# R7FA4L1BD register map
Vendor: Renesas Electronics Corporation; Series: RA4; File version: 0.90.02
CPU: CM33 r0p4, little endian, MPU, FPU, VTOR, 4 interrupt priority bits, 96 interrupts
Registers are 32-bit, read-write, reset 0x0 unless marked. A register's access mark holds for its fields unless they carry their own. Offsets are from the block's base; [hi:lo] are bit positions; {n}, {i} and the like mark numbered series.

## IIC0 — Inter,Integrated Circuit 0
Base 0x4009F000
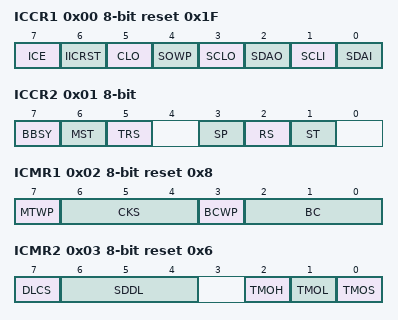
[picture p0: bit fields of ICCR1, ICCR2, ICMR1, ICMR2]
0x00 ICCR1 8-bit reset 0x1F — I2C Bus Control Register 1
  [7] ICE — I2C Bus Interface Enable
  [6] IICRST — I2C Bus Interface Internal Reset
  [5] CLO — Extra SCL Clock Cycle Output
  [4] SOWP wo — SCLO/SDAO Write Protect
  [3] SCLO — SCL Output Control/Monitor
  [2] SDAO — SDA Output Control/Monitor
  [1] SCLI ro — SCL Line Monitor
  [0] SDAI ro — SDA Line Monitor
0x01 ICCR2 8-bit — I2C Bus Control Register 2
  [7] BBSY ro — Bus Busy Detection Flag
  [6] MST — Master/Slave Mode
  [5] TRS — Transmit/Receive Mode
  [3] SP — Stop Condition Issuance Request
  [2] RS — Restart Condition Issuance Request
  [1] ST — Start Condition Issuance Request
0x02 ICMR1 8-bit reset 0x8 — I2C Bus Mode Register 1
  [7] MTWP — MST/TRS Write Protect
  [6:4] CKS — Internal Reference Clock Select
  [3] BCWP wo — BC Write Protect
  [2:0] BC — Bit Counter
0x03 ICMR2 8-bit reset 0x6 — I2C Bus Mode Register 2
  [7] DLCS — SDA Output Delay Clock Source Select
  [6:4] SDDL — SDA Output Delay Counter
  [2] TMOH — Timeout H Count Control
  [1] TMOL — Timeout L Count Control
  [0] TMOS — Timeout Detection Time Select
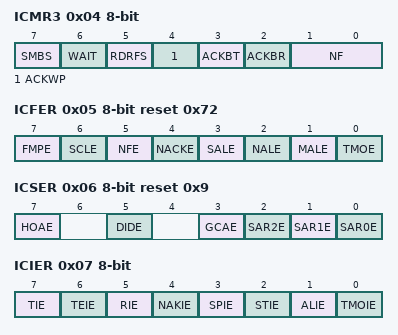
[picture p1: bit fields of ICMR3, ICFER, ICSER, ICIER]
0x04 ICMR3 8-bit — I2C Bus Mode Register 3
  [7] SMBS — SMBus/I2C Bus Select
  [6] WAIT — Low,hold is released by reading ICDRR.
  [5] RDRFS — RDRF Flag Set Timing Select
  [4] ACKWP — ACKBT Write Protect
  [3] ACKBT — Transmit Acknowledge
  [2] ACKBR ro — Receive Acknowledge
  [1:0] NF — Noise Filter Stage Select
0x05 ICFER 8-bit reset 0x72 — I2C Bus Function Enable Register
  [7] FMPE — Fast,Mode Plus Enable
  [6] SCLE — SCL Synchronous Circuit Enable
  [5] NFE — Digital Noise Filter Circuit Enable
  [4] NACKE — NACK Reception Transfer Suspension Enable
  [3] SALE — Slave Arbitration,Lost Detection Enable
  [2] NALE — NACK Transmission Arbitration,Lost Detection Enable
  [1] MALE — Master Arbitration,Lost Detection Enable
  [0] TMOE — Timeout Function Enable
0x06 ICSER 8-bit reset 0x9 — I2C Bus Status Enable Register
  [7] HOAE — Host Address Enable
  [5] DIDE — Device,ID Address Detection Enable
  [3] GCAE — General Call Address Enable
  [2] SAR2E — Slave Address Register 2 Enable
  [1] SAR1E — Slave Address Register 1 Enable
  [0] SAR0E — Slave Address Register 0 Enable
0x07 ICIER 8-bit — I2C Bus Interrupt Enable Register
  [7] TIE — Transmit Data Empty Interrupt Request Enable
  [6] TEIE — Transmit End Interrupt Request Enable
  [5] RIE — Receive Data Full Interrupt Request Enable
  [4] NAKIE — NACK Reception Interrupt Request Enable
  [3] SPIE — Stop Condition Detection Interrupt Request Enable
  [2] STIE — Start Condition Detection Interrupt Request Enable
  [1] ALIE — Arbitration,Lost Interrupt Request Enable
  [0] TMOIE — Timeout Interrupt Request Enable
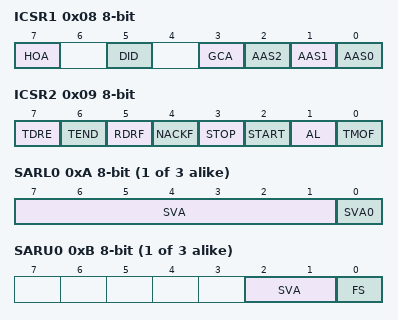
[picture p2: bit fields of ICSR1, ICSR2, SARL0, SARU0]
0x08 ICSR1 8-bit — I2C Bus Status Register 1
  [7] HOA — Host Address Detection Flag
  [5] DID — Device,ID Address Detection Flag
  [3] GCA — General Call Address Detection Flag
  [2] AAS2 — Slave Address 2 Detection Flag
  [1] AAS1 — Slave Address 1 Detection Flag
  [0] AAS0 — Slave Address 0 Detection Flag
0x09 ICSR2 8-bit — I2C Bus Status Register 2
  [7] TDRE ro — Transmit Data Empty Flag
  [6] TEND — Transmit End Flag
  [5] RDRF — Receive Data Full Flag
  [4] NACKF — NACK Detection Flag
  [3] STOP — Stop Condition Detection Flag
  [2] START — Start Condition Detection Flag
  [1] AL — Arbitration,Lost Flag
  [0] TMOF — Timeout Detection Flag
{0xA+2i} SARL{i} (i=0..2) 8-bit — Slave Address Register Ly
  [7:1] SVA — 7-bit Address/10-bit Address Lower Bits
  [0] SVA0 — 10-bit Address LSB
{0xB+2i} SARU{i} (i=0..2) 8-bit — Slave Address Register Uy
  [2:1] SVA — 10-bit Address Upper Bits
  [0] FS — 7-bit/10-bit Address Format Select
0x10 ICBRL 8-bit reset 0xFF — I2C Bus Bit Rate Low,Level Register
  [4:0] BRL — Bit Rate Low,Level Period
0x11 ICBRH 8-bit reset 0xFF — I2C Bus Bit Rate High,Level Register
  [4:0] BRH — Bit Rate High,Level Period
0x12 ICDRT 8-bit reset 0xFF — I2C Bus Transmit Data Register
0x13 ICDRR 8-bit — I2C Bus Receive Data Register
